VERSION ""

NS_ :

BS_: 500

BU_: Vector__XXX

BO_ 200 MSG_0C8: 8 Vector__XXX
 SG_ Engine_Speed : 48|16@0+ (1,0) [0|10000] "rpm" Vector__XXX

BO_ 250 MSG_0FA: 8 Vector__XXX
 SG_ Ignition_On : 1|1@1+ (1,0) [0|0] "" Vector__XXX

BO_ 256 MSG_100: 8 Vector__XXX
 SG_ Gear : 0|8@1+ (0.5,-1.5) [0|0] "" Vector__XXX

BO_ 300 MSG_12C: 8 Vector__XXX
 SG_ Oil_Pressure : 24|8@1+ (0.04,0) [0|0] "bar" Vector__XXX

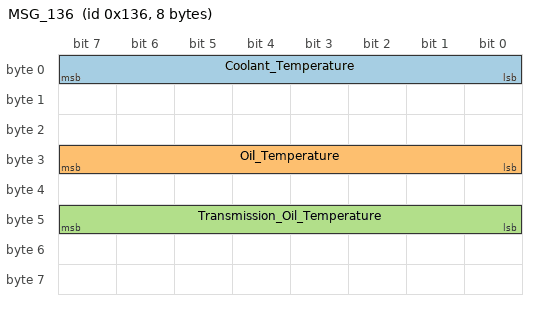
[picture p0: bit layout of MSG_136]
BO_ 310 MSG_136: 8 Vector__XXX
 SG_ Coolant_Temperature : 0|8@1+ (1,-30) [0|0] "��C" Vector__XXX
 SG_ Oil_Temperature : 24|8@1+ (1,-30) [0|0] "��C" Vector__XXX
 SG_ Transmission_Oil_Temperature : 40|8@1+ (1,-30) [0|0] "��C" Vector__XXX

BO_ 340 MSG_154: 8 Vector__XXX
 SG_ Steering_Angle : 0|16@0- (1,0) [0|0] "��" Vector__XXX
